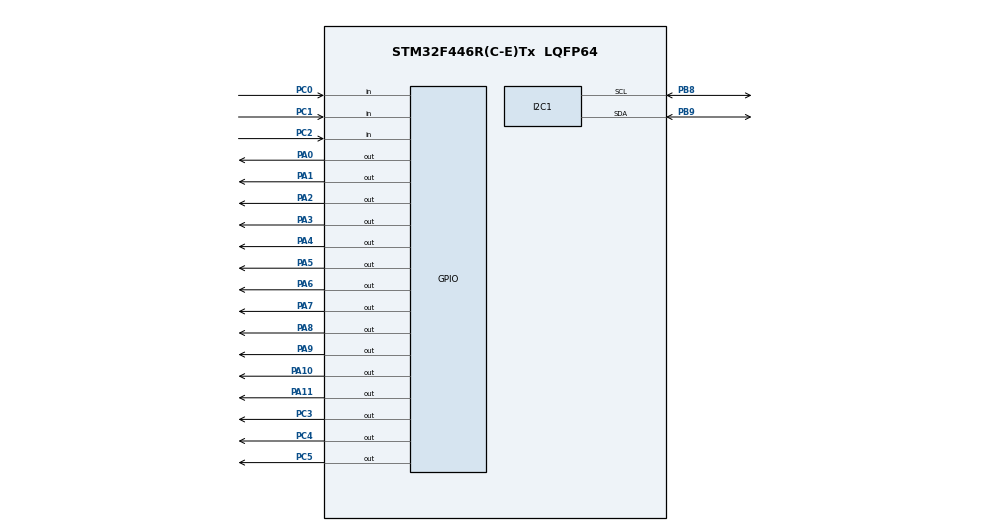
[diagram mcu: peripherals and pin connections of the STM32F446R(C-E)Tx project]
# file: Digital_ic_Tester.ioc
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I2C1.I2C_Mode=I2C_Fast
Mcu.Family=STM32F4
Mcu.Name=STM32F446R(C-E)Tx
Mcu.Package=LQFP64
NVIC.PriorityGroup=NVIC_PRIORITYGROUP_4
PA0-WKUP.GPIO_ModeDefaultOutputPP=GPIO_MODE_OUTPUT_PP
PA0-WKUP.GPIO_PuPd=GPIO_NOPULL
PA0-WKUP.GPIO_Speed=GPIO_SPEED_FREQ_HIGH
PA0-WKUP.PinState=GPIO_PIN_RESET
PA0-WKUP.Signal=GPIO_Output
PA1.GPIO_ModeDefaultOutputPP=GPIO_MODE_OUTPUT_PP
PA1.GPIO_PuPd=GPIO_NOPULL
PA1.GPIO_Speed=GPIO_SPEED_FREQ_HIGH
PA1.PinState=GPIO_PIN_RESET
PA1.Signal=GPIO_Output
PA10.GPIO_ModeDefaultOutputPP=GPIO_MODE_OUTPUT_PP
PA10.GPIO_PuPd=GPIO_NOPULL
PA10.GPIO_Speed=GPIO_SPEED_FREQ_HIGH
PA10.PinState=GPIO_PIN_RESET
PA10.Signal=GPIO_Output
PA11.GPIO_ModeDefaultOutputPP=GPIO_MODE_OUTPUT_PP
PA11.GPIO_PuPd=GPIO_NOPULL
PA11.GPIO_Speed=GPIO_SPEED_FREQ_HIGH
PA11.PinState=GPIO_PIN_RESET
PA11.Signal=GPIO_Output
PA2.GPIO_ModeDefaultOutputPP=GPIO_MODE_OUTPUT_PP
PA2.GPIO_PuPd=GPIO_NOPULL
PA2.GPIO_Speed=GPIO_SPEED_FREQ_HIGH
PA2.PinState=GPIO_PIN_RESET
PA2.Signal=GPIO_Output
PA3.GPIO_ModeDefaultOutputPP=GPIO_MODE_OUTPUT_PP
PA3.GPIO_PuPd=GPIO_NOPULL
PA3.GPIO_Speed=GPIO_SPEED_FREQ_HIGH
PA3.PinState=GPIO_PIN_RESET
PA3.Signal=GPIO_Output
PA4.GPIO_ModeDefaultOutputPP=GPIO_MODE_OUTPUT_PP
PA4.GPIO_PuPd=GPIO_NOPULL
PA4.GPIO_Speed=GPIO_SPEED_FREQ_HIGH
PA4.PinState=GPIO_PIN_RESET
PA4.Signal=GPIO_Output
PA5.GPIO_ModeDefaultOutputPP=GPIO_MODE_OUTPUT_PP
PA5.GPIO_PuPd=GPIO_NOPULL
PA5.GPIO_Speed=GPIO_SPEED_FREQ_HIGH
PA5.PinState=GPIO_PIN_RESET
PA5.Signal=GPIO_Output
PA6.GPIO_ModeDefaultOutputPP=GPIO_MODE_OUTPUT_PP
PA6.GPIO_PuPd=GPIO_NOPULL
PA6.GPIO_Speed=GPIO_SPEED_FREQ_HIGH
PA6.PinState=GPIO_PIN_RESET
PA6.Signal=GPIO_Output
PA7.GPIO_ModeDefaultOutputPP=GPIO_MODE_OUTPUT_PP
PA7.GPIO_PuPd=GPIO_NOPULL
PA7.GPIO_Speed=GPIO_SPEED_FREQ_HIGH
PA7.PinState=GPIO_PIN_RESET
PA7.Signal=GPIO_Output
PA8.GPIO_ModeDefaultOutputPP=GPIO_MODE_OUTPUT_PP
PA8.GPIO_PuPd=GPIO_NOPULL
PA8.GPIO_Speed=GPIO_SPEED_FREQ_HIGH
PA8.PinState=GPIO_PIN_RESET
PA8.Signal=GPIO_Output
PA9.GPIO_ModeDefaultOutputPP=GPIO_MODE_OUTPUT_PP
PA9.GPIO_PuPd=GPIO_NOPULL
PA9.GPIO_Speed=GPIO_SPEED_FREQ_HIGH
PA9.PinState=GPIO_PIN_RESET
PA9.Signal=GPIO_Output
PB8.Mode=I2C
PB8.Signal=I2C1_SCL
PB9.Mode=I2C
PB9.Signal=I2C1_SDA
PC0.GPIO_Mode=GPIO_MODE_INPUT
PC0.GPIO_PuPd=GPIO_PULLUP
PC0.Signal=GPIO_Input
PC1.GPIO_Mode=GPIO_MODE_INPUT
PC1.GPIO_PuPd=GPIO_PULLUP
PC1.Signal=GPIO_Input
PC2.GPIO_Mode=GPIO_MODE_INPUT
PC2.GPIO_PuPd=GPIO_PULLUP
PC2.Signal=GPIO_Input
PC3.GPIO_ModeDefaultOutputPP=GPIO_MODE_OUTPUT_PP
PC3.GPIO_PuPd=GPIO_NOPULL
PC3.GPIO_Speed=GPIO_SPEED_FREQ_LOW
PC3.PinState=GPIO_PIN_RESET
PC3.Signal=GPIO_Output
PC4.GPIO_ModeDefaultOutputPP=GPIO_MODE_OUTPUT_PP
PC4.GPIO_PuPd=GPIO_NOPULL
PC4.GPIO_Speed=GPIO_SPEED_FREQ_LOW
PC4.PinState=GPIO_PIN_RESET
PC4.Signal=GPIO_Output
PC5.GPIO_ModeDefaultOutputPP=GPIO_MODE_OUTPUT_PP
PC5.GPIO_PuPd=GPIO_NOPULL
PC5.GPIO_Speed=GPIO_SPEED_FREQ_LOW
PC5.PinState=GPIO_PIN_RESET
PC5.Signal=GPIO_Output
ProjectManager.HeapSize=0x200
ProjectManager.StackSize=0x400
ProjectManager.TargetToolchain=STM32CubeIDE
RCC.AHBFreq_Value=90000000
RCC.APB1CLKDivider=RCC_HCLK_DIV2
RCC.APB1Freq_Value=45000000
RCC.APB1TimFreq_Value=90000000
RCC.APB2Freq_Value=90000000
RCC.APB2TimFreq_Value=90000000
RCC.CortexFreq_Value=90000000
RCC.HCLKFreq_Value=90000000
RCC.PLLN=180
RCC.SYSCLKFreq_VALUE=90000000
RCC.SYSCLKSource=RCC_SYSCLKSOURCE_PLLCLK
RCC.USBFreq_Value=90000000
RCC.VCOOutputFreq_Value=180000000
board=custom

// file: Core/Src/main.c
/**
  ******************************************************************************
  * @file           : main.c
  * @brief          : Auto-Detecting Digital IC Tester - STM32 Nucleo-F446RE
  ******************************************************************************
  */

#include "main.h"
/* USER CODE BEGIN Includes */
#include "tester.h"
#include "i2c1_reg.h"
/* USER CODE END Includes */

static void SystemClock_Config(void);
static void MX_GPIO_Init(void);
static void MX_I2C1_Init(void);

int main(void)
{
    SystemClock_Config();
    SystemCoreClockUpdate();
    SysTick_Config(SystemCoreClock / 1000U);

    MX_GPIO_Init();
    MX_I2C1_Init();

    /* USER CODE BEGIN 2 */
    Tester_Run();
    /* USER CODE END 2 */

    while (1)
    {
    }
}

static void SystemClock_Config(void)
{
    RCC->APB1ENR |= RCC_APB1ENR_PWREN;
    PWR->CR = (PWR->CR & ~PWR_CR_VOS) | PWR_CR_VOS;
    RCC->CR |= RCC_CR_HSION;
    while ((RCC->CR & RCC_CR_HSIRDY) == 0U)
    {
    }

    /* Disable the PLL before reconfiguring it. */
    RCC->CR &= ~RCC_CR_PLLON;
    while ((RCC->CR & RCC_CR_PLLRDY) != 0U)
    {
    }

    /* PLLSRC = HSI, PLLM = 16, PLLN = 180, PLLP = /2, PLLQ = 2 */
    RCC->PLLCFGR = RCC_PLLCFGR_PLLSRC_HSI
                  | (16U  << RCC_PLLCFGR_PLLM_Pos)
                  | (180U << RCC_PLLCFGR_PLLN_Pos)
                  | (0U   << RCC_PLLCFGR_PLLP_Pos)   /* 00 = PLLP /2 */
                  | (2U   << RCC_PLLCFGR_PLLQ_Pos);

    RCC->CR |= RCC_CR_PLLON;
    while ((RCC->CR & RCC_CR_PLLRDY) == 0U)
    {
    }

    /* Flash latency = 2 wait states, required for 90MHz HCLK at VOS1. */
    FLASH->ACR = (FLASH->ACR & ~FLASH_ACR_LATENCY) | FLASH_ACR_LATENCY_2WS;
    while ((FLASH->ACR & FLASH_ACR_LATENCY) != FLASH_ACR_LATENCY_2WS)
    {
    }

    /* AHB = SYSCLK/1, APB1 = HCLK/2, APB2 = HCLK/1 - set the prescalers
     * BEFORE switching SYSCLK to the PLL. */
    RCC->CFGR = (RCC->CFGR & ~(RCC_CFGR_HPRE | RCC_CFGR_PPRE1 | RCC_CFGR_PPRE2))
              | RCC_CFGR_HPRE_DIV1 | RCC_CFGR_PPRE1_DIV2 | RCC_CFGR_PPRE2_DIV1;

    /* Switch SYSCLK source to the PLL and wait for the switch to complete. */
    RCC->CFGR = (RCC->CFGR & ~RCC_CFGR_SW) | RCC_CFGR_SW_PLL;
    while ((RCC->CFGR & RCC_CFGR_SWS) != RCC_CFGR_SWS_PLL)
    {
        /* Original code called Error_Handler() on a HAL_RCC_ClockConfig()
         * failure/timeout. */
    }
}

/**
  * @brief I2C1 Init - PB8=SCL, PB9=SDA, Fast mode 400kHz, duty cycle 2
  */
static void MX_I2C1_Init(void)
{
    I2C1_Init();
}

/**
  * @brief GPIO Init - matches DigitalIC_Tester.ioc exactly:
  *        PA0-PA11 : GPIO output, push-pull, no pull, initially LOW  (ZIF interface)
  *        PC0/1/2  : GPIO input, pull-up                             (UP/DOWN/OK buttons)
  *        PC3      : GPIO output, initially LOW                      (PASS LED)
  *        PC4      : GPIO output, initially LOW                      (FAIL LED)
  *        PC5      : GPIO output, initially LOW                      (BUZZER)
  */
static void MX_GPIO_Init(void)
{
    const uint16_t zif_pins  = GPIO_PIN_0 | GPIO_PIN_1 | GPIO_PIN_2 | GPIO_PIN_3
                              | GPIO_PIN_4 | GPIO_PIN_5 | GPIO_PIN_6 | GPIO_PIN_7
                              | GPIO_PIN_8 | GPIO_PIN_9 | GPIO_PIN_10 | GPIO_PIN_11;
    const uint16_t ind_pins  = LED_PASS_Pin | LED_FAIL_Pin | BUZZER_Pin;
    const uint16_t btn_pins  = BTN_UP_Pin | BTN_DOWN_Pin | BTN_OK_Pin;

    RCC->AHB1ENR |= RCC_AHB1ENR_GPIOCEN | RCC_AHB1ENR_GPIOAEN;

    /* Ensure all outputs start LOW before configuring as outputs (BSRR
     * upper half-word = "reset" bits, same effect as
     * HAL_GPIO_WritePin(..., GPIO_PIN_RESET)). */
    GPIOA->BSRR = ((uint32_t)zif_pins) << 16;
    GPIOC->BSRR = ((uint32_t)ind_pins) << 16;

    /* --- PA0-PA11 : ZIF socket interface, output push-pull, no pull, high speed --- */
    for (uint32_t pin = 0U; pin <= 11U; pin++)
    {
        GPIOA->MODER   = (GPIOA->MODER   & ~(3U << (pin * 2U))) | (1U << (pin * 2U)); /* output */
        GPIOA->OTYPER  &= ~(1U << pin);                                               /* push-pull */
        GPIOA->OSPEEDR = (GPIOA->OSPEEDR & ~(3U << (pin * 2U))) | (2U << (pin * 2U)); /* high speed */
        GPIOA->PUPDR   &= ~(3U << (pin * 2U));                                        /* no pull */
    }

    /* --- PC0/1/2 : buttons, input, pull-up --- */
    for (uint32_t pin = 0U; pin <= 2U; pin++)
    {
        GPIOC->MODER &= ~(3U << (pin * 2U));                                      /* input */
        GPIOC->PUPDR  = (GPIOC->PUPDR & ~(3U << (pin * 2U))) | (1U << (pin * 2U)); /* pull-up */
    }
    (void)btn_pins; /* pin numbers used directly above; kept for readability */

    /* --- PC3/4/5 : PASS LED, FAIL LED, buzzer - output push-pull, low speed --- */
    for (uint32_t pin = 3U; pin <= 5U; pin++)
    {
        GPIOC->MODER   = (GPIOC->MODER   & ~(3U << (pin * 2U))) | (1U << (pin * 2U)); /* output */
        GPIOC->OTYPER  &= ~(1U << pin);                                               /* push-pull */
        GPIOC->OSPEEDR &= ~(3U << (pin * 2U));                                        /* low speed */
        GPIOC->PUPDR   &= ~(3U << (pin * 2U));                                        /* no pull */
    }
}

void Error_Handler(void)
{
    __disable_irq();
    while (1)
    {
    }
}
